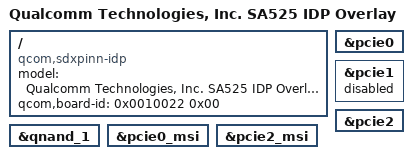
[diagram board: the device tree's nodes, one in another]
/dts-v1/;
/plugin/;

#include "sa525m-idp.dtsi"

/ {
	model = "Qualcomm Technologies, Inc. SA525 IDP Overlay";
	compatible = "qcom,sdxpinn-idp",
		"qcom,sdxpinn", "qcom,idp";
	qcom,board-id = <0x0010022 0x00>;
};

&qnand_1 {
	status = "ok";
};

&pcie0 {
	status = "ok";
};

&pcie0_msi {
	status = "ok";
};

&pcie1 {
	status = "disabled";
};

&pcie2 {
	status = "ok";
};

&pcie2_msi {
	status = "ok";
};
